# RL6845_IP_SVD register map
Vendor: Realtek
Registers are 32-bit, read-write, reset 0x0 unless marked. A register's access mark holds for its fields unless they carry their own. Offsets are from the block's base; [hi:lo] are bit positions; {n}, {i} and the like mark numbered series.

## DEBUGTIMER_REG
Base 0x41015000
0x00 DBGT_CTRL reset 0x1 — Debug Timer control register
  [0] enable — Debug timer enable. 1: The counter is enabled. 0: The counter is disabled.
0x04 DBGT_CRV — Debug Timer count register
  [31:0] dbgt_crv — Continue to count from 0 once it's reached 32'hFFFFFFFF.
0x08 DBGT_ATOM_INC ro — Debug Timer atom read increase register
  [31:0] dbgt_atom_inc — Each read will increase 1 and return to the increased value to bus.
0x0C DBGT_ATOM — Debug Timer atom register
  [31:0] dbgt_atom — Return the last increased value of atom counter.
0x10 DBGT_SCRATCH — Debug Timer scratch register
  [31:0] dbgt_scratch — Reserved
0x14 REG_DBGTIM_DUMMY reset 0xFFFF — Debug Timer Dummy Register

## PMC_TIMER_REG
Base 0x41016000
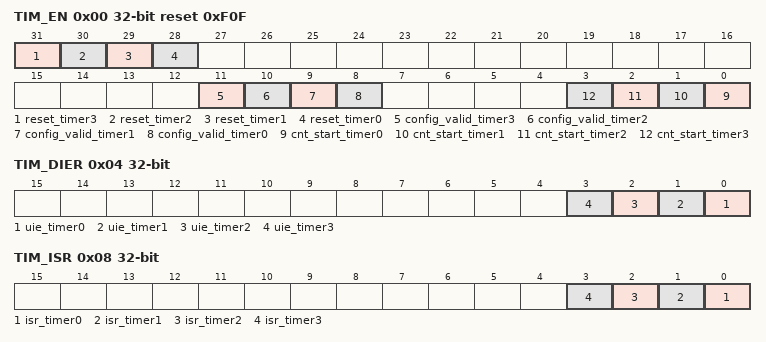
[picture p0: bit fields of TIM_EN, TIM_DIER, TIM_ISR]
0x00 TIM_EN access per field reset 0xF0F — TIM enable register
  [31] reset_timer3 wo — Writing 1 will cause a pulse reset timer1. Please wait for 3 work clk before new timer configuration 1: valid 0: not valid
  [30] reset_timer2 wo — Writing 1 will cause a pulse reset timer1. Please wait for 3 work clk before new timer configuration 1: valid 0: not valid
  [29] reset_timer1 wo — Writing 1 will cause a pulse reset timer1. Please wait for 3 work clk before new timer configuration 1: valid 0: not valid
  [28] reset_timer0 wo — Writing 1 will cause a pulse reset timer0. Please wait for 3 work clk before new timer configuration 1: valid 0: not valid
  [11] config_valid_timer3 ro — TIM_SET configuration valid or not. 1: valid 0: not valid if compare option enable, 1: vaild value is seted 0: set option is on going
  [10] config_valid_timer2 ro — TIM_SET configuration valid or not 1: valid 0: not valid
  [9] config_valid_timer1 ro — TIM_SET configuration valid or not 1: valid 0: not valid
  [8] config_valid_timer0 ro — TIM_SET configuration valid or not 1: valid 0: not valid
  [n] cnt_start_timer{n} rw (n=0..3) — enable the timer{n} counter. 1:enable 0:disable
0x04 TIM_DIER — TIM interupt enable register
  [n] uie_timer{n} (n=0..3) — 1: enable update interrupt 0: disable update interrupt
0x08 TIM_ISR ro — TIM interrupt status register
  [n] isr_timer{n} (n=0..3) — Timer interrupt status 0: no interrupt 1: interrupt occurs Write 1 to clear interrupts in interrupt handler.
{0xC+4i} TIM_CNT{i} ro reset 0xFFFFFFFF (i=0..3) — TIM counter{i}
  [31:0] cnt{i} — counter value, counter will stop automatically when it counts down to zero.
{0x1C+4i} TIM_SET{i} (i=0..3) — TIM set register{i}
  [31:0] tim_set{i} — Set a countdown value. This value come into force when TIM_EN register bit is enabled. counter will count down from this value immediately.
0x2C TIM_com_en reset 0xF — TIM compare register
  [3:0] com_en — enable compare option.The set cnt value takes effect only when it is greater than the actual cnt value 0:disable 1:enable [0] : control tim0 set ...... [3]: control tim3 set
0x30 PMCTIM_DUMMY reset 0xFFFF — PMCTimer Dummy Register

## IWDG_REG
Base 0x41008C00
Same registers: WDG0_REG 0x41008D00, WDG2_REG 0x41008D80, WDG1_REG_S 0x51008D40
0x00 WDG_MKEYR — WDG Magic Key register
  [15:0] MKEY — 0x6969: enable access to register WDG_CR/WDG_RLR/WDG_WINR 0x5A5A: reload WDG counter 0x3C3C: enable WDG function
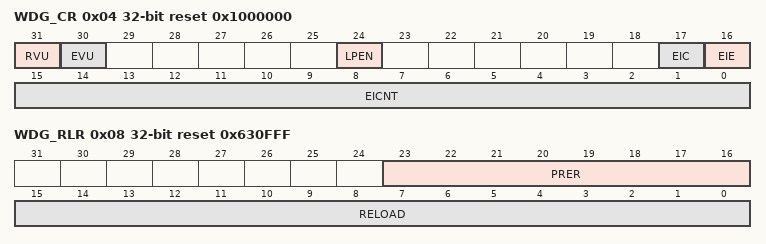
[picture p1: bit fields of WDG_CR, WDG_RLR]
0x04 WDG_CR access per field reset 0x1000000 — WDG Control regsietr
  [31] RVU ro — Watchdog counter update by reload command
  [30] EVU ro — Watchdog early interrupt function update
  [24] LPEN rw — Low power enable 0: WDG will gating when system goes into sleep mode 1: WDG keep running when system goes into sleep mode
  [17] EIC wo — Write '1' clear the early interrupt
  [16] EIE rw — Watchdog early interrupt enable
  [15:0] EICNT rw — Early interrupt trigger threshold
0x08 WDG_RLR reset 0x630FFF — WDG Relaod register
  [23:16] PRER — Prescaler counter, configuration only allowed before WDG enable IWDG: 0x63 System WDG: 0x1F
  [15:0] RELOAD — Reload value for watchdog counter
0x0C WDG_WINR reset 0xFFFF — WDG Window Register
  [15:0] WINDOW — Watchdog feed protect window register
0x10 IWDG_DUMMY reset 0xFF — WDG Dummy Register
  [15:0] dummy — Reserved for HW
